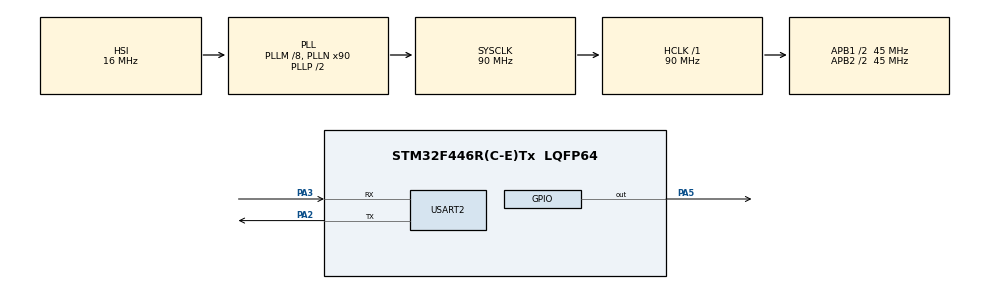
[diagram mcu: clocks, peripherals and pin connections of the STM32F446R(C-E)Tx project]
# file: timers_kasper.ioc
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Mcu.Family=STM32F4
RCC.CortexFreq_Value=90000000
RCC.APB1CLKDivider=RCC_HCLK_DIV2
RCC.SYSCLKSource=RCC_SYSCLKSOURCE_PLLCLK
ProjectManager.StackSize=0x400
PA3.Mode=Asynchronous
ProjectManager.TargetToolchain=STM32CubeIDE
RCC.HCLKFreq_Value=90000000
RCC.APB2TimFreq_Value=90000000
RCC.USBFreq_Value=90000000
RCC.AHBFreq_Value=90000000
PA5.Signal=GPIO_Output
NVIC.TIM8_TRG_COM_TIM14_IRQn=true\:0\:0\:false\:false\:true\:true\:true
board=custom
RCC.VCOOutputFreq_Value=180000000
TIM14.Period=1000 - 1
RCC.APB2Freq_Value=45000000
Mcu.Name=STM32F446R(C-E)Tx
TIM14.Prescaler=90 - 1
PA2.Signal=USART2_TX
RCC.SYSCLKFreq_VALUE=90000000
Mcu.Package=LQFP64
USART2.VirtualMode=VM_ASYNC
ProjectManager.HeapSize=0x200
NVIC.PriorityGroup=NVIC_PRIORITYGROUP_4
RCC.APB2CLKDivider=RCC_HCLK_DIV2
RCC.PLLM=8
RCC.PLLN=90
RCC.APB1TimFreq_Value=90000000
PA2.Mode=Asynchronous
VP_TIM14_VS_ClockSourceINT.Mode=Enable_Timer
RCC.APB1Freq_Value=45000000
PA3.Signal=USART2_RX

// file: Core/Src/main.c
/* USER CODE BEGIN Header */
/**
  ******************************************************************************
  * @file           : main.c
  * @brief          : Main program body
  ******************************************************************************
  * @attention
  *
  * <h2><center>&copy; Copyright (c) 2021 STMicroelectronics.
  * All rights reserved.</center></h2>
  *
  * This software component is licensed by ST under BSD 3-Clause license,
  * the "License"; You may not use this file except in compliance with the
  * License. You may obtain a copy of the License at:
  *                        opensource.org/licenses/BSD-3-Clause
  *
  ******************************************************************************
  */
/* USER CODE END Header */
#include "main.h"

TIM_HandleTypeDef htim14;

UART_HandleTypeDef huart2;

void SystemClock_Config(void);
static void MX_GPIO_Init(void);
static void MX_USART2_UART_Init(void);
static void MX_TIM14_Init(void);

int main(void)
{

  /* MCU Configuration--------------------------------------------------------*/

  /* Reset of all peripherals, Initializes the Flash interface and the Systick. */
  HAL_Init();

  /* Configure the system clock */
  SystemClock_Config();

  /* Initialize all configured peripherals */
  MX_GPIO_Init();
  MX_USART2_UART_Init();
  MX_TIM14_Init();
  /* USER CODE BEGIN 2 */

  // Start timer
  HAL_TIM_Base_Start_IT(&htim14);

  /* USER CODE END 2 */

  /* Infinite loop */
  while (1)
  {

  }
}

void SystemClock_Config(void)
{
  RCC_OscInitTypeDef RCC_OscInitStruct = {0};
  RCC_ClkInitTypeDef RCC_ClkInitStruct = {0};

  /** Configure the main internal regulator output voltage
  */
  __HAL_RCC_PWR_CLK_ENABLE();
  __HAL_PWR_VOLTAGESCALING_CONFIG(PWR_REGULATOR_VOLTAGE_SCALE3);
  /** Initializes the RCC Oscillators according to the specified parameters
  * in the RCC_OscInitTypeDef structure.
  */
  RCC_OscInitStruct.OscillatorType = RCC_OSCILLATORTYPE_HSI;
  RCC_OscInitStruct.HSIState = RCC_HSI_ON;
  RCC_OscInitStruct.HSICalibrationValue = RCC_HSICALIBRATION_DEFAULT;
  RCC_OscInitStruct.PLL.PLLState = RCC_PLL_ON;
  RCC_OscInitStruct.PLL.PLLSource = RCC_PLLSOURCE_HSI;
  RCC_OscInitStruct.PLL.PLLM = 8;
  RCC_OscInitStruct.PLL.PLLN = 90;
  RCC_OscInitStruct.PLL.PLLP = RCC_PLLP_DIV2;
  RCC_OscInitStruct.PLL.PLLQ = 2;
  RCC_OscInitStruct.PLL.PLLR = 2;
  if (HAL_RCC_OscConfig(&RCC_OscInitStruct) != HAL_OK)
  {
    Error_Handler();
  }
  /** Initializes the CPU, AHB and APB buses clocks
  */
  RCC_ClkInitStruct.ClockType = RCC_CLOCKTYPE_HCLK|RCC_CLOCKTYPE_SYSCLK
                              |RCC_CLOCKTYPE_PCLK1|RCC_CLOCKTYPE_PCLK2;
  RCC_ClkInitStruct.SYSCLKSource = RCC_SYSCLKSOURCE_PLLCLK;
  RCC_ClkInitStruct.AHBCLKDivider = RCC_SYSCLK_DIV1;
  RCC_ClkInitStruct.APB1CLKDivider = RCC_HCLK_DIV2;
  RCC_ClkInitStruct.APB2CLKDivider = RCC_HCLK_DIV2;

  if (HAL_RCC_ClockConfig(&RCC_ClkInitStruct, FLASH_LATENCY_2) != HAL_OK)
  {
    Error_Handler();
  }
}

static void MX_TIM14_Init(void)
{

  htim14.Instance = TIM14;
  htim14.Init.Prescaler = 90 - 1;
  htim14.Init.CounterMode = TIM_COUNTERMODE_UP;
  htim14.Init.Period = 1000 - 1;
  htim14.Init.ClockDivision = TIM_CLOCKDIVISION_DIV1;
  htim14.Init.AutoReloadPreload = TIM_AUTORELOAD_PRELOAD_DISABLE;
  if (HAL_TIM_Base_Init(&htim14) != HAL_OK)
  {
    Error_Handler();
  }

}

static void MX_USART2_UART_Init(void)
{

  huart2.Instance = USART2;
  huart2.Init.BaudRate = 115200;
  huart2.Init.WordLength = UART_WORDLENGTH_8B;
  huart2.Init.StopBits = UART_STOPBITS_1;
  huart2.Init.Parity = UART_PARITY_NONE;
  huart2.Init.Mode = UART_MODE_TX_RX;
  huart2.Init.HwFlowCtl = UART_HWCONTROL_NONE;
  huart2.Init.OverSampling = UART_OVERSAMPLING_16;
  if (HAL_UART_Init(&huart2) != HAL_OK)
  {
    Error_Handler();
  }

}

static void MX_GPIO_Init(void)
{
  GPIO_InitTypeDef GPIO_InitStruct = {0};

  /* GPIO Ports Clock Enable */
  __HAL_RCC_GPIOA_CLK_ENABLE();

  /*Configure GPIO pin Output Level */
  HAL_GPIO_WritePin(GPIOA, GPIO_PIN_5, GPIO_PIN_RESET);

  /*Configure GPIO pin : PA5 */
  GPIO_InitStruct.Pin = GPIO_PIN_5;
  GPIO_InitStruct.Mode = GPIO_MODE_OUTPUT_PP;
  GPIO_InitStruct.Pull = GPIO_NOPULL;
  GPIO_InitStruct.Speed = GPIO_SPEED_FREQ_LOW;
  HAL_GPIO_Init(GPIOA, &GPIO_InitStruct);

}

/* USER CODE BEGIN 4 */
// Callback: timer has rolled over
void HAL_TIM_PeriodElapsedCallback(TIM_HandleTypeDef *htim)
{
  // Check which version of the timer triggered this callback and toggle LED
  if (htim == &htim14 )
  {
    HAL_GPIO_TogglePin(GPIOA, GPIO_PIN_5);
  }
}
/* USER CODE END 4 */

void Error_Handler(void)
{
  __disable_irq();
  while (1)
  {
  }
}

/************************ (C) COPYRIGHT STMicroelectronics *****END OF FILE****/
